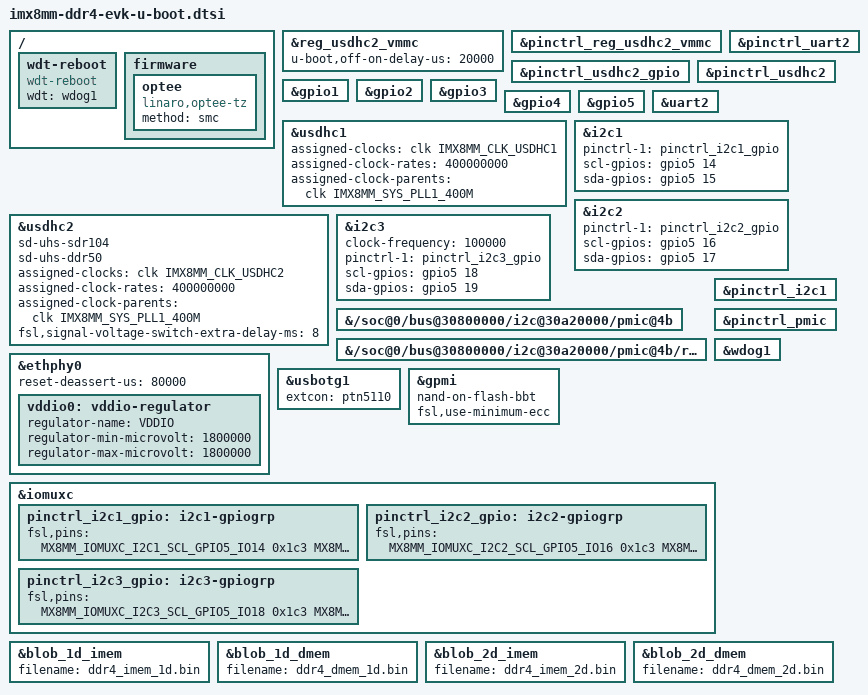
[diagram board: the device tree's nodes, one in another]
// SPDX-License-Identifier: GPL-2.0+
/*
 * Copyright 2020 NXP
 */

#include "imx8mm-u-boot.dtsi"

/ {
	wdt-reboot {
		compatible = "wdt-reboot";
		wdt = <&wdog1>;
		bootph-pre-ram;
	};

	firmware {
		optee {
			compatible = "linaro,optee-tz";
			method = "smc";
		};
	};
};

&reg_usdhc2_vmmc {
	u-boot,off-on-delay-us = <20000>;
	bootph-pre-ram;
};

&pinctrl_reg_usdhc2_vmmc {
	bootph-pre-ram;
};

&pinctrl_uart2 {
	bootph-pre-ram;
};

&pinctrl_usdhc2_gpio {
	bootph-pre-ram;
};

&pinctrl_usdhc2 {
	bootph-pre-ram;
};

&gpio1 {
	bootph-pre-ram;
};

&gpio2 {
	bootph-pre-ram;
};

&gpio3 {
	bootph-pre-ram;
};

&gpio4 {
	bootph-pre-ram;
};

&gpio5 {
	bootph-pre-ram;
};

&uart2 {
	bootph-pre-ram;
};

&usdhc1 {
	bootph-pre-ram;
	assigned-clocks = <&clk IMX8MM_CLK_USDHC1>;
	assigned-clock-rates = <400000000>;
	assigned-clock-parents = <&clk IMX8MM_SYS_PLL1_400M>;
};

&usdhc2 {
	bootph-pre-ram;
	sd-uhs-sdr104;
	sd-uhs-ddr50;
	assigned-clocks = <&clk IMX8MM_CLK_USDHC2>;
	assigned-clock-rates = <400000000>;
	assigned-clock-parents = <&clk IMX8MM_SYS_PLL1_400M>;
	fsl,signal-voltage-switch-extra-delay-ms = <8>;
};

&i2c1 {
	pinctrl-names = "default", "gpio";
	pinctrl-1 = <&pinctrl_i2c1_gpio>;
	scl-gpios = <&gpio5 14 GPIO_ACTIVE_HIGH>;
	sda-gpios = <&gpio5 15 GPIO_ACTIVE_HIGH>;
	bootph-pre-ram;
};

&i2c2 {
	pinctrl-names = "default", "gpio";
	pinctrl-1 = <&pinctrl_i2c2_gpio>;
	scl-gpios = <&gpio5 16 GPIO_ACTIVE_HIGH>;
	sda-gpios = <&gpio5 17 GPIO_ACTIVE_HIGH>;
};

&i2c3 {
	clock-frequency = <100000>;
	pinctrl-names = "default", "gpio";
	pinctrl-1 = <&pinctrl_i2c3_gpio>;
	scl-gpios = <&gpio5 18 GPIO_ACTIVE_HIGH>;
	sda-gpios = <&gpio5 19 GPIO_ACTIVE_HIGH>;
};

&{/soc@0/bus@30800000/i2c@30a20000/pmic@4b} {
	bootph-pre-ram;
};

&{/soc@0/bus@30800000/i2c@30a20000/pmic@4b/regulators} {
	bootph-pre-ram;
};

&pinctrl_i2c1 {
	bootph-pre-ram;
};

&pinctrl_pmic {
	bootph-pre-ram;
};

&ethphy0 {
	reset-deassert-us = <80000>;

	vddio0: vddio-regulator {
		regulator-name = "VDDIO";
		regulator-min-microvolt = <1800000>;
		regulator-max-microvolt = <1800000>;
	};
};

&wdog1 {
	bootph-pre-ram;
};

&usbotg1 {
	status = "okay";
	extcon = <&ptn5110>;
};

&gpmi {
	nand-on-flash-bbt;
	fsl,use-minimum-ecc;
};

&iomuxc {
	pinctrl_i2c1_gpio: i2c1-gpiogrp {
		fsl,pins = <
			MX8MM_IOMUXC_I2C1_SCL_GPIO5_IO14        		0x1c3
			MX8MM_IOMUXC_I2C1_SDA_GPIO5_IO15        	0x1c3
		>;
	};

	pinctrl_i2c2_gpio: i2c2-gpiogrp {
		fsl,pins = <
			MX8MM_IOMUXC_I2C2_SCL_GPIO5_IO16        		0x1c3
			MX8MM_IOMUXC_I2C2_SDA_GPIO5_IO17        	0x1c3
		>;
	};

	pinctrl_i2c3_gpio: i2c3-gpiogrp {
		fsl,pins = <
			MX8MM_IOMUXC_I2C3_SCL_GPIO5_IO18        		0x1c3
			MX8MM_IOMUXC_I2C3_SDA_GPIO5_IO19        	0x1c3
		>;
	};
};

&blob_1d_imem {
			filename = "ddr4_imem_1d.bin";
};

&blob_1d_dmem {
			filename = "ddr4_dmem_1d.bin";
};

&blob_2d_imem {
			filename = "ddr4_imem_2d.bin";
};

&blob_2d_dmem {
			filename = "ddr4_dmem_2d.bin";
};
